# PIC16LF84A register map
Vendor: Microchip
Architecture 16xxxx. Special function registers and configuration words.
Registers are 8-bit, read-write, no defined reset value unless marked. A register's access mark holds for its fields unless they carry their own. Addresses are absolute, and some are shared; only a register's first bit layout is shown; lines under a group give offsets from that group; [hi:lo] are bit positions; {n}, {i} and the like mark numbered series; 'fields as' and 'values as' point back to an identical list; <NAME> marks a mode.

## Further device data
pins=1: RA2; 2: RA3; 3: RA4/T0CKI; 4: MCLR; 5: Vss; 6: RB0/INT; 7: RB1; 8: RB2; 9: RB3; 10: RB4; 11: RB5; 12: RB6; 13: RB7; 14: Vdd; 15: OSC2/CLKOUT; 16: OSC1/CLKIN; 17: RA0; 18: RA1

## SFR
0x00 INDF access not given
0x01 TMR0 — (power-on value xxxxxxxx)
0x02 PCL reset 0x0
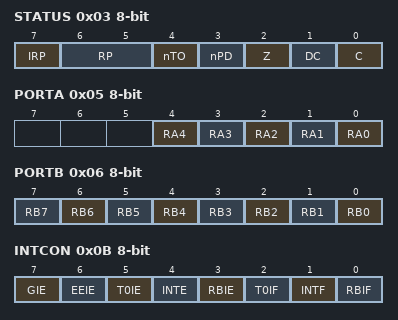
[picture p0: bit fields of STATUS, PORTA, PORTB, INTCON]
0x03 STATUS — (power-on value 00011xxx)
  [7] IRP, [6:5] RP, [4] nTO ro, [3] nPD ro, [2] Z, [1] DC, [0] C
0x04 FSR — (power-on value xxxxxxxx)
0x05 PORTA — (power-on value ---xxxxx)
  [n] RA{n} (n=0..4)
0x06 PORTB — (power-on value xxxxxxxx)
  [n] RB{n} (n=0..7)
0x08 EEDATA — (power-on value xxxxxxxx)
0x09 EEADR — (power-on value xxxxxxxx)
0x0A PCLATH reset 0x0
  [4:0] PCLATH
0x0B INTCON — (power-on value 0000000x)
  [7] GIE, [6] EEIE, [5] T0IE, [4] INTE, [3] RBIE, [2] T0IF, [1] INTF, [0] RBIF
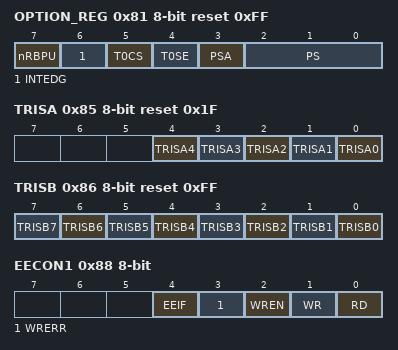
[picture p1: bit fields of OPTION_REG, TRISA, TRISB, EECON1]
0x81 OPTION_REG reset 0xFF
  [7] nRBPU, [6] INTEDG, [5] T0CS, [4] T0SE, [3] PSA, [2:0] PS
0x85 TRISA reset 0x1F
  [n] TRISA{n} (n=0..4)
0x86 TRISB reset 0xFF
  [n] TRISB{n} (n=0..7)
0x88 EECON1 — (power-on value ---0x000)
  [4] EEIF
  [3] WRERR
  [2] WREN
  [1] WR — (can only be set)
  [0] RD — (can only be set)
0x89 EECON2 wo

## CONFIG — Configuration words, addresses in ProgramSpace
0x2007 CONFIG 14-bit reset 0x3FFF
  [13:4] CP — Code Protection bit
    0x3FF=OFF (Code protection disabled); 0=ON (All program memory is code protected)
  [3] PWRTE — Power-up Timer Enable bit
    1=OFF (Power-up Timer is disabled); 0=ON (Power-up Timer is enabled)
  [2] WDTE — Watchdog Timer
    1=ON (WDT enabled); 0=OFF (WDT disabled)
  [1:0] FOSC — Oscillator Selection bits
    3=EXTRC (RC oscillator); 2=HS (HS oscillator); 1=XT (XT oscillator); 0=LP (LP oscillator)
